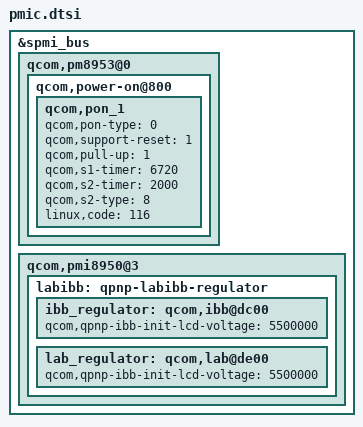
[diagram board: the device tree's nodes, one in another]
#include <dt-bindings/pinctrl/qcom,pmic-gpio.h>

&spmi_bus {
	qcom,pm8953@0 {
		qcom,power-on@800 {
			qcom,pon_1 {
				qcom,pon-type = <0>;
				qcom,support-reset = <1>;
				qcom,pull-up = <1>;
				qcom,s1-timer = <6720>;
				qcom,s2-timer = <2000>;
				qcom,s2-type = <8>;
				linux,code = <116>;
			};
		};
		/delete-node/ qcom,pm8953_typec@bf00;
	};
};

&spmi_bus {
	qcom,pmi8950@3 {
		labibb: qpnp-labibb-regulator {
			status = "ok";
			ibb_regulator: qcom,ibb@dc00 {
				/delete-property/
					qcom,qpnp-ibb-use-default-voltage;
				qcom,qpnp-ibb-init-lcd-voltage = <5500000>;
			};

			lab_regulator: qcom,lab@de00 {
				/delete-property/
					qcom,qpnp-ibb-use-default-voltage;
				qcom,qpnp-ibb-init-lcd-voltage = <5500000>;
			};
		};
	};
};
